AUTOSAR XML (schema 00048)
package /MICROSAR/Dcm_swc
  mode declaration group DcmDiagnosticSessionControl: category=EXPLICIT_ORDER, initial-mode=DEFAULT_SESSION, on-transition-value=255
    mode DEFAULT_SESSION: value=1
    mode PROGRAMMING_SESSION: value=2
    mode EXTENDED_SESSION: value=3
  mode declaration group DcmEcuReset: category=EXPLICIT_ORDER, initial-mode=NONE, on-transition-value=7
    7 x mode:
      NONE: value=0
      HARD: value=1
      KEYONOFF: value=2
      SOFT: value=3
      JUMPTOBOOTLOADER: value=4
      JUMPTOSYSSUPPLIERBOOTLOADER: value=5
      EXECUTE: value=6
  mode declaration group DcmCommunicationControl: category=EXPLICIT_ORDER, initial-mode=DCM_ENABLE_RX_TX_NORM, on-transition-value=12
    12 x mode:
      DCM_ENABLE_RX_TX_NORM: value=0
      DCM_ENABLE_RX_DISABLE_TX_NORM: value=1
      DCM_DISABLE_RX_ENABLE_TX_NORM: value=2
      DCM_DISABLE_RX_TX_NORMAL: value=3
      DCM_ENABLE_RX_TX_NM: value=4
      DCM_ENABLE_RX_DISABLE_TX_NM: value=5
      DCM_DISABLE_RX_ENABLE_TX_NM: value=6
      DCM_DISABLE_RX_TX_NM: value=7
      DCM_ENABLE_RX_TX_NORM_NM: value=8
      DCM_ENABLE_RX_DISABLE_TX_NORM_NM: value=9
      DCM_DISABLE_RX_ENABLE_TX_NORM_NM: value=10
      DCM_DISABLE_RX_TX_NORM_NM: value=11
  data type mapping set DcmMappingSet  # Contains mapping for ModeDeclarationGroups which are provided by Dcm.
    mode-request-type-maps:
      implementation-data-type=Dcm_EcuResetType, mode-group=DcmEcuReset
      implementation-data-type=Dcm_DiagnosticSessionControlType, mode-group=DcmDiagnosticSessionControl
      implementation-data-type=Dcm_CommunicationModeType, mode-group=DcmCommunicationControl
package /MICROSAR/Dcm_swc/DataTypes
  13 x impl type:
    Dcm_ConfirmationStatusType: compu {0=DCM_RES_POS_OK, 1=DCM_RES_POS_NOT_OK, 2=DCM_RES_NEG_OK, 3=DCM_RES_NEG_NOT_OK}, range raw 0..3, implementation-data-type=uint8
    Dcm_OpStatusType: compu {0=DCM_INITIAL, 1=DCM_PENDING, 2=DCM_CANCEL, 3=DCM_FORCE_RCRRP_OK, 64=DCM_FORCE_RCRRP_NOT_OK}, range raw 0..64, implementation-data-type=uint8
    Dcm_NegativeResponseCodeType:
      compu {0=DCM_E_POSITIVERESPONSE, 16=DCM_E_GENERALREJECT, 17=DCM_E_SERVICENOTSUPPORTED, 18=DCM_E_SUBFUNCTIONNOTSUPPORTED, 19=DCM_E_INCORRECTMESSAGELENGTHORINVALIDFORMAT, 20=DCM_E_RESPONSETOOLONG, 33=DCM_E_BUSYREPEATREQUEST, 34=DCM_E_CONDITIONSNOTCORRECT, 36=DCM_E_REQUESTSEQUENCEERROR, 37=DCM_E_NORESPONSEFROMSUBNETCOMPONENT, 38=DCM_E_FAILUREPREVENTSEXECUTIONOFREQUESTEDACTION, 49=DCM_E_REQUESTOUTOFRANGE, 51=DCM_E_SECURITYACCESSDENIED, 52=DCM_E_AUTHENTICATIONREQUIRED, 53=DCM_E_INVALIDKEY, 54=DCM_E_EXCEEDNUMBEROFATTEMPTS, 55=DCM_E_REQUIREDTIMEDELAYNOTEXPIRED, 80=DCM_E_CVF_INVALIDTIMEPERIOD, 81=DCM_E_CVF_INVALIDSIGNATURE, 82=DCM_E_CVF_INVALIDCHAINOFTRUST, 83=DCM_E_CVF_INVALIDTYPE, 84=DCM_E_CVF_INVALIDFORMAT, 85=DCM_E_CVF_INVALIDCONTENT, 86=DCM_E_CVF_INVALIDSCOPE, 87=DCM_E_CVF_INVALIDCERTIFICATEREVOKED, 88=DCM_E_OWNERSHIPVERIFICATIONFAILED, 89=DCM_E_CHALLENGECALCULATIONFAILED, 112=DCM_E_UPLOADDOWNLOADNOTACCEPTED, 113=DCM_E_TRANSFERDATASUSPENDED, 114=DCM_E_GENERALPROGRAMMINGFAILURE, 115=DCM_E_WRONGBLOCKSEQUENCECOUNTER, 120=DCM_E_REQUESTCORRECTLYRECEIVEDRESPONSEPENDING, 126=DCM_E_SUBFUNCTIONNOTSUPPORTEDINACTIVESESSION, 127=DCM_E_SERVICENOTSUPPORTEDINACTIVESESSION, 129=DCM_E_RPMTOOHIGH, 130=DCM_E_RPMTOOLOW, 131=DCM_E_ENGINEISRUNNING, 132=DCM_E_ENGINEISNOTRUNNING, 133=DCM_E_ENGINERUNTIMETOOLOW, 134=DCM_E_TEMPERATURETOOHIGH, 135=DCM_E_TEMPERATURETOOLOW, 136=DCM_E_VEHICLESPEEDTOOHIGH, 137=DCM_E_VEHICLESPEEDTOOLOW, 138=DCM_E_THROTTLE_PEDALTOOHIGH, 139=DCM_E_THROTTLE_PEDALTOOLOW, 140=DCM_E_TRANSMISSIONRANGENOTINNEUTRAL, 141=DCM_E_TRANSMISSIONRANGENOTINGEAR, 143=DCM_E_BRAKESWITCH_NOTCLOSED, 144=DCM_E_SHIFTERLEVERNOTINPARK, 145=DCM_E_TORQUECONVERTERCLUTCHLOCKED, 146=DCM_E_VOLTAGETOOHIGH, 147=DCM_E_VOLTAGETOOLOW, 240..249=DCM_E_VMSCNC_0..DCM_E_VMSCNC_9, 250=DCM_E_VMSCNC_A, 251=DCM_E_VMSCNC_B, 252=DCM_E_VMSCNC_C, 253=DCM_E_VMSCNC_D, 254=DCM_E_VMSCNC_E}
      range raw 0..255
      implementation-data-type=uint8
    Dcm_ProtocolType: compu {0=DCM_OBD_ON_CAN, 1=DCM_OBD_ON_FLEXRAY, 2=DCM_OBD_ON_IP, 3=DCM_UDS_ON_CAN, 4=DCM_UDS_ON_FLEXRAY, 5=DCM_UDS_ON_IP, 12=DCM_NO_ACTIVE_PROTOCOL, 240..254=DCM_SUPPLIER_1..DCM_SUPPLIER_15}, range raw 0..254, implementation-data-type=uint8
    Dcm_RequestKindType: compu {0=DCM_REQ_KIND_NONE, 1=DCM_REQ_KIND_EXTERNAL, 2=DCM_REQ_KIND_ROE}, range raw 0..2, implementation-data-type=uint8
    Dcm_SesCtrlType: compu {1=DCM_DEFAULT_SESSION, 2=DCM_PROGRAMMING_SESSION, 3=DCM_EXTENDED_DIAGNOSTIC_SESSION}, range raw 0..3, implementation-data-type=uint8
    Dcm_DiagnosticSessionControlType: compu {1=DCM_ENUM_DEFAULT_SESSION, 2=DCM_ENUM_PROGRAMMING_SESSION, 3=DCM_ENUM_EXTENDED_SESSION}, range raw 0..255, implementation-data-type=uint8
    Dcm_CommunicationModeType:
      compu {0=DCM_ENABLE_RX_TX_NORM, 1=DCM_ENABLE_RX_DISABLE_TX_NORM, 2=DCM_DISABLE_RX_ENABLE_TX_NORM, 3=DCM_DISABLE_RX_TX_NORMAL, 4=DCM_ENABLE_RX_TX_NM, 5=DCM_ENABLE_RX_DISABLE_TX_NM, 6=DCM_DISABLE_RX_ENABLE_TX_NM, 7=DCM_DISABLE_RX_TX_NM, 8=DCM_ENABLE_RX_TX_NORM_NM, 9=DCM_ENABLE_RX_DISABLE_TX_NORM_NM, 10=DCM_DISABLE_RX_ENABLE_TX_NORM_NM, 11=DCM_DISABLE_RX_TX_NORM_NM}
      range raw 0..255
      implementation-data-type=uint8
    Dcm_SecLevelType: compu {0=DCM_SEC_LEV_LOCKED, 3=DCM_SEC_LEV_L3}, range raw 0..3, implementation-data-type=uint8
    Dcm_EcuResetType: compu {0=DCM_ENUM_NONE, 1=DCM_ENUM_HARD, 2=DCM_ENUM_KEYONOFF, 3=DCM_ENUM_SOFT, 4=DCM_ENUM_JUMPTOBOOTLOADER, 5=DCM_ENUM_JUMPTOSYSSUPPLIERBOOTLOADER, 6=DCM_ENUM_EXECUTE}, range raw 0..255, implementation-data-type=uint8
    Dcm_Data32ByteType: category=ARRAY, sw-calibration-access=READ-ONLY
      element Dcm_Data32ByteTypeElement: array-size=32, array-size-semantics=FIXED-SIZE, implementation-data-type=uint8
    Dcm_Data64ByteType: category=ARRAY, sw-calibration-access=READ-ONLY
      element Dcm_Data64ByteTypeElement: array-size=64, array-size-semantics=FIXED-SIZE, implementation-data-type=uint8
    Dcm_Data8ByteType: category=ARRAY, sw-calibration-access=READ-ONLY
      element Dcm_Data8ByteTypeElement: array-size=8, array-size-semantics=FIXED-SIZE, implementation-data-type=uint8
package /MICROSAR/Dcm_swc/Interfaces
  mode switch interface DcmDiagnosticSessionControl: is-service=true, service-kind=DIAGNOSTIC-COMMUNICATION-MANAGER
    mode group DcmDiagnosticSessionControl: type=DcmDiagnosticSessionControl
  client server interface DCMServices: is-service=true, service-kind=DIAGNOSTIC-COMMUNICATION-MANAGER
    6 x operation:
      GetActiveProtocol: possible-error=E_OK
        arg ActiveProtocol: type=Dcm_ProtocolType, direction=OUT
      GetSesCtrlType: possible-error=E_OK
        arg SesCtrlType: type=Dcm_SesCtrlType, direction=OUT
      ResetToDefaultSession: possible-error=E_OK
      SetActiveDiagnostic: possible-error=E_OK
        arg active: type=boolean, direction=IN
      GetRequestKind: possible-error=DCMServices/E_NOT_OK
        arg TesterSourceAddress: type=uint16, direction=IN
        arg RequestKind: type=Dcm_RequestKindType, direction=OUT
      GetSecurityLevel: possible-error=E_OK
        arg SecLevel: type=Dcm_SecLevelType, direction=OUT
    error E_OK: error-code=0
    error E_NOT_OK: error-code=1
  mode switch interface DcmEcuReset: is-service=true, service-kind=DIAGNOSTIC-COMMUNICATION-MANAGER
    mode group DcmEcuReset: type=DcmEcuReset
  mode switch interface DcmCommunicationControl_ComMConf_ComMChannel_ComMChannel_Vlan1: is-service=true, service-kind=DIAGNOSTIC-COMMUNICATION-MANAGER
    mode group DcmCommunicationControl_ComMConf_ComMChannel_ComMChannel_Vlan1: type=DcmCommunicationControl
  client server interface SecurityAccess_Level_3: is-service=true, service-kind=DIAGNOSTIC-COMMUNICATION-MANAGER
    4 x operation:
      GetSeed: possible-error=[SecurityAccess_Level_3/E_NOT_OK, SecurityAccess_Level_3/DCM_E_PENDING]
        arg OpStatus: type=Dcm_OpStatusType, direction=IN
        arg Seed: type=Dcm_Data32ByteType, direction=OUT
        arg ErrorCode: type=Dcm_NegativeResponseCodeType, direction=OUT
      CompareKey: possible-error=[SecurityAccess_Level_3/E_NOT_OK, SecurityAccess_Level_3/DCM_E_PENDING, DCM_E_COMPARE_KEY_FAILED]
        arg Key: type=Dcm_Data64ByteType, direction=IN
        arg OpStatus: type=Dcm_OpStatusType, direction=IN
        arg ErrorCode: type=Dcm_NegativeResponseCodeType, direction=OUT
      GetSecurityAttemptCounter: possible-error=[SecurityAccess_Level_3/E_NOT_OK, SecurityAccess_Level_3/DCM_E_PENDING]
        arg OpStatus: type=Dcm_OpStatusType, direction=IN
        arg AttemptCounter: type=uint8, direction=OUT
      SetSecurityAttemptCounter: possible-error=[SecurityAccess_Level_3/E_NOT_OK, SecurityAccess_Level_3/DCM_E_PENDING]
        arg OpStatus: type=Dcm_OpStatusType, direction=IN
        arg AttemptCounter: type=uint8, direction=IN
    error E_NOT_OK: error-code=1
    error DCM_E_PENDING: error-code=10
    error DCM_E_COMPARE_KEY_FAILED: error-code=11
  client server interface RoutineServices_DcmDspRoutine_Get_Link_Quality_Start: is-service=true, service-kind=DIAGNOSTIC-COMMUNICATION-MANAGER
    operation Start: possible-error=[RoutineServices_DcmDspRoutine_Get_Link_Quality_Start/E_NOT_OK, RoutineServices_DcmDspRoutine_Get_Link_Quality_Start/DCM_E_PENDING, DCM_E_FORCE_RCRRP]
      4 x arg:
        Port_Number: type=uint8, direction=IN
        OpStatus: type=Dcm_OpStatusType, direction=IN
        Link_Quality: type=uint8, direction=OUT
        ErrorCode: type=Dcm_NegativeResponseCodeType, direction=OUT
    operation RequestResults: possible-error=[RoutineServices_DcmDspRoutine_Get_Link_Quality_Start/E_NOT_OK, RoutineServices_DcmDspRoutine_Get_Link_Quality_Start/DCM_E_PENDING, DCM_E_FORCE_RCRRP]
      arg OpStatus: type=Dcm_OpStatusType, direction=IN
      arg ErrorCode: type=Dcm_NegativeResponseCodeType, direction=OUT
    error E_NOT_OK: error-code=1
    error DCM_E_PENDING: error-code=10
    error DCM_E_FORCE_RCRRP: error-code=12
  client server interface DataServices_Version_Info: is-service=true, service-kind=DIAGNOSTIC-COMMUNICATION-MANAGER
    operation ReadData: possible-error=[DataServices_Version_Info/E_NOT_OK, DataServices_Version_Info/DCM_E_PENDING]
      arg OpStatus: type=Dcm_OpStatusType, direction=IN
      arg Data: type=Dcm_Data8ByteType, direction=OUT
    operation ConditionCheckRead: possible-error=[DataServices_Version_Info/E_NOT_OK, DataServices_Version_Info/DCM_E_PENDING]
      arg OpStatus: type=Dcm_OpStatusType, direction=IN
      arg ErrorCode: type=Dcm_NegativeResponseCodeType, direction=OUT
    operation WriteData: possible-error=[DataServices_Version_Info/E_NOT_OK, DataServices_Version_Info/DCM_E_PENDING]
      arg Data: type=Dcm_Data8ByteType, direction=IN
      arg OpStatus: type=Dcm_OpStatusType, direction=IN
      arg ErrorCode: type=Dcm_NegativeResponseCodeType, direction=OUT
    error E_NOT_OK: error-code=1
    error DCM_E_PENDING: error-code=10
package /MICROSAR/Dcm_swc/ComponentTypes
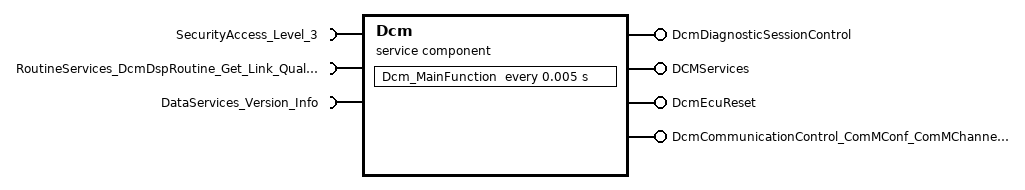
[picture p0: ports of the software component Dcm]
  service sw component type Dcm: category=SERVICE_COMPONENT
    4 x provide port:
      DcmDiagnosticSessionControl: provided-interface=DcmDiagnosticSessionControl
      DCMServices: provided-interface=DCMServices
      DcmEcuReset: mode-switch-sender-com-spec{mode-group=DcmEcuReset, mode-switched-ack=timeout=0}, provided-interface=DcmEcuReset
      DcmCommunicationControl_ComMConf_ComMChannel_ComMChannel_Vlan1: provided-interface=DcmCommunicationControl_ComMConf_ComMChannel_ComMChannel_Vlan1
    require port SecurityAccess_Level_3: required-interface=SecurityAccess_Level_3
    require port RoutineServices_DcmDspRoutine_Get_Link_Quality_Start: required-interface=RoutineServices_DcmDspRoutine_Get_Link_Quality_Start
    require port DataServices_Version_Info: required-interface=DataServices_Version_Info
    behavior DcmInternalBehavior: data-type-mapping=DcmMappingSet, handle-termination-and-restart=NO-SUPPORT, included-data-type-set=data-type=[Dcm_ConfirmationStatusType, Dcm_OpStatusType, Dcm_NegativeResponseCodeType, Dcm_ProtocolType, Dcm_RequestKindType, Dcm_SecLevelType, Dcm_SesCtrlType, Dcm_EcuResetType, Dcm_DiagnosticSessionControlType, Dcm_CommunicationModeType]
      timing event Timer_Dcm_MainFunction: start-on-event=Dcm_MainFunction, period=0.005
      6 x operation invoked event:
        OpEventGetActiveProtocol_GetActiveProtocol_DCMServices: start-on-event=GetActiveProtocol, operation=DCMServices.GetActiveProtocol
        OpEventGetSesCtrlType_GetSesCtrlType_DCMServices: start-on-event=GetSesCtrlType, operation=DCMServices.GetSesCtrlType
        OpEventResetToDefaultSession_ResetToDefaultSession_DCMServices: start-on-event=ResetToDefaultSession, operation=DCMServices.ResetToDefaultSession
        OpEventSetActiveDiagnostic_SetActiveDiagnostic_DCMServices: start-on-event=SetActiveDiagnostic, operation=DCMServices.SetActiveDiagnostic
        OpEventGetRequestKind_GetRequestKind_DCMServices: start-on-event=GetRequestKind, operation=DCMServices.GetRequestKind
        OpEventGetSecurityLevel_GetSecurityLevel_DCMServices: start-on-event=GetSecurityLevel, operation=DCMServices.GetSecurityLevel
      port-api-options:
        enable-take-address=true, indirect-api=false, port=DcmEcuReset
        enable-take-address=true, indirect-api=false, port=DcmDiagnosticSessionControl
        enable-take-address=true, indirect-api=false, port=DcmCommunicationControl_ComMConf_ComMChannel_ComMChannel_Vlan1
        enable-take-address=true, indirect-api=false, port=DCMServices
        enable-take-address=true, indirect-api=false, port=SecurityAccess_Level_3
        enable-take-address=true, indirect-api=false, port=RoutineServices_DcmDspRoutine_Get_Link_Quality_Start
        enable-take-address=true, indirect-api=false, port=DataServices_Version_Info
      7 x runnable:
        Dcm_MainFunction
          mode switch point ModeSwitchPointDcm_MainFunction_DcmDiagnosticSessionControl_DcmDiagnosticSessionControl: mode-group=DcmDiagnosticSessionControl.DcmDiagnosticSessionControl
          mode switch point ModeSwitchPointDcm_MainFunction_DcmEcuReset_DcmEcuReset: mode-group=DcmEcuReset.DcmEcuReset
          mode switch point ModeSwitchPointDcm_MainFunction_DcmCommunicationControl_ComMConf_ComMChannel_ComMChannel_Vlan1_DcmCommunicationControl_f417d05c: mode-group=DcmCommunicationControl_ComMConf_ComMChannel_ComMChannel_Vlan1.DcmCommunicationControl_ComMConf_ComMChannel_ComMChannel_Vlan1
          9 x sync call, all with timeout=0:
            OpServerCallDcm_MainFunction_GetSeed_SecurityAccess_Level_3: operation=SecurityAccess_Level_3.GetSeed
            OpServerCallDcm_MainFunction_CompareKey_SecurityAccess_Level_3: operation=SecurityAccess_Level_3.CompareKey
            OpServerCallDcm_MainFunction_GetSecurityAttemptCounter_SecurityAccess_Level_3: operation=SecurityAccess_Level_3.GetSecurityAttemptCounter
            OpServerCallDcm_MainFunction_SetSecurityAttemptCounter_SecurityAccess_Level_3: operation=SecurityAccess_Level_3.SetSecurityAttemptCounter
            OpServerCallDcm_MainFunction_Start_RoutineServices_DcmDspRoutine_Get_Link_Quality_Start: operation=RoutineServices_DcmDspRoutine_Get_Link_Quality_Start.Start
            OpServerCallDcm_MainFunction_RequestResults_RoutineServices_DcmDspRoutine_Get_Link_Quality_Start: operation=RoutineServices_DcmDspRoutine_Get_Link_Quality_Start.RequestResults
            OpServerCallDcm_MainFunction_ReadData_DataServices_Version_Info: operation=DataServices_Version_Info.ReadData
            OpServerCallDcm_MainFunction_ConditionCheckRead_DataServices_Version_Info: operation=DataServices_Version_Info.ConditionCheckRead
            OpServerCallDcm_MainFunction_WriteData_DataServices_Version_Info: operation=DataServices_Version_Info.WriteData
        GetActiveProtocol: can-be-invoked-concurrently=true, symbol=Dcm_GetActiveProtocol
        GetSesCtrlType: can-be-invoked-concurrently=true, symbol=Dcm_GetSesCtrlType
        ResetToDefaultSession: can-be-invoked-concurrently=true, symbol=Dcm_ResetToDefaultSession
        SetActiveDiagnostic: can-be-invoked-concurrently=true, symbol=Dcm_SetActiveDiagnostic
        GetRequestKind: can-be-invoked-concurrently=true, symbol=Dcm_GetRequestKind
        GetSecurityLevel: can-be-invoked-concurrently=true, symbol=Dcm_GetSecurityLevel
  swc implementation DcmImplementation: programming-language=C, behavior=DcmInternalBehavior
